# CH32V205 register map
Vendor: WCH Ltd.; File version: 1.0
Registers are 32-bit, read-write, reset 0x0 unless marked. A register's access mark holds for its fields unless they carry their own. Offsets are from the block's base; [hi:lo] are bit positions; {n}, {i} and the like mark numbered series.

## PWR — Power control
Base 0x40007000
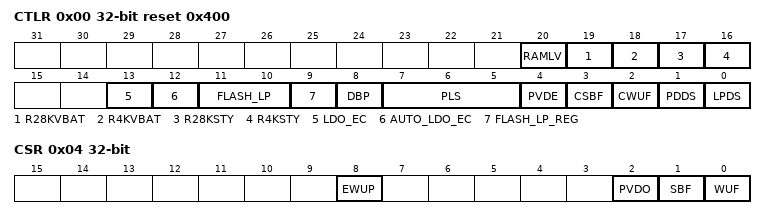
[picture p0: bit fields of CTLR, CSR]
0x00 CTLR reset 0x400 — Power control register (PWR_CTRL)
  [20] RAMLV — Ram LV Enable
  [19] R28KVBAT — VBAT 28k ram enable
  [18] R4KVBAT — VBAT 4k ram enable
  [17] R28KSTY — standby 28k ram enable
  [16] R4KSTY — standby 4k ram enable
  [13] LDO_EC — LDO energy conservation mode enable
  [12] AUTO_LDO_EC — Auto energy conservation mode of LDO after entering stop mode
  [11:10] FLASH_LP — configuration FLASH status
  [9] FLASH_LP_REG — FLASH Low-power enable
  [8] DBP — Disable Backup Domain write protection
  [7:5] PLS — PVD Level Selection
  [4] PVDE — Power Voltage Detector Enable
  [3] CSBF — Clear STANDBY Flag
  [2] CWUF — Clear Wake-up Flag
  [1] PDDS — Power Down Deep Sleep
  [0] LPDS — Low Power Deep Sleep
0x04 CSR access per field — Power control register(PWR_CSR)
  [8] EWUP rw — Enable WKUP pin
  [2] PVDO ro — PVD Output
  [1] SBF ro — STANDBY Flag
  [0] WUF ro — Wake-Up Flag

## EXTEN — Exten configuration
Base 0x40023800
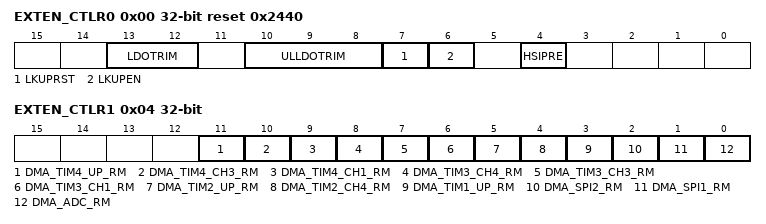
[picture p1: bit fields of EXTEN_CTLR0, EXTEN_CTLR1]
0x00 EXTEN_CTLR0 reset 0x2440 — EXTEN control register 0
  [13:12] LDOTRIM
  [10:8] ULLDOTRIM
  [7] LKUPRST — LOCKUP RESET
  [6] LKUPEN — LOCKUP_Eable
  [4] HSIPRE — Whether HSI is divided
0x04 EXTEN_CTLR1 — EXTEN control register 1
  [11] DMA_TIM4_UP_RM — Mapping of TIM4_UP on the DMA channel
  [10] DMA_TIM4_CH3_RM — Mapping of IM4_CH3 on the DMA channel
  [9] DMA_TIM4_CH1_RM — Mapping of TIM4_CH1 on the DMA channel
  [8] DMA_TIM3_CH4_RM — Mapping of TIM3_CH4 on the DMA channel
  [7] DMA_TIM3_CH3_RM — Mapping of TIM3_CH3 on the DMA channel
  [6] DMA_TIM3_CH1_RM — Mapping of TIM3_CH1 on the DMA channel
  [5] DMA_TIM2_UP_RM — Mapping of TIM2_UP on the DMA channel
  [4] DMA_TIM2_CH4_RM — Mapping of TIM2_CH4 on the DMA channel
  [3] DMA_TIM1_UP_RM — Mapping of TIM1_UP on the DMA channel
  [2] DMA_SPI2_RM — Mapping of SPI2 on the DMA channel
  [1] DMA_SPI1_RM — Mapping of SPI1 on the DMA channel
  [0] DMA_ADC_RM — Mapping of ADC on the DMA channel

## GPIOA — General purpose I/O
Base 0x40010800
Same registers: GPIOB 0x40010C00, GPIOC 0x40011000, GPIOD 0x40011400, GPIOE 0x40011800
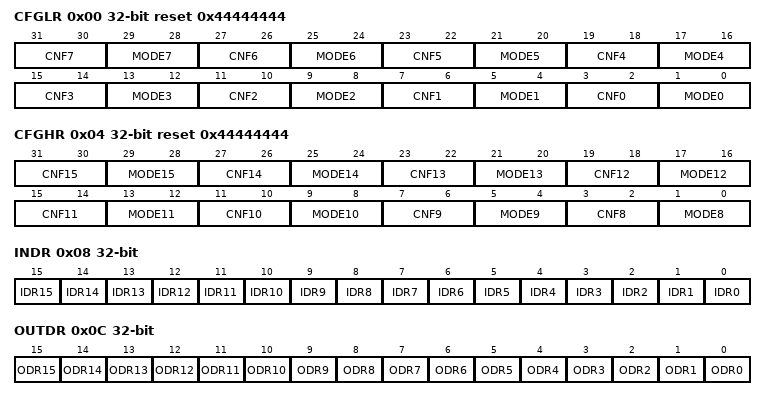
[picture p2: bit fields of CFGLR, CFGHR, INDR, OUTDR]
0x00 CFGLR reset 0x44444444 — Port configuration register low(GPIOn_CFGLR)
  [31:30] CNF7 — Port n.7 configuration bits
  [29:28] MODE7 — Port n.7 mode bits
  [27:26] CNF6 — Port n.6 configuration bits
  [25:24] MODE6 — Port n.6 mode bits
  [23:22] CNF5 — Port n.5 configuration bits
  [21:20] MODE5 — Port n.5 mode bits
  [19:18] CNF4 — Port n.4 configuration bits
  [17:16] MODE4 — Port n.4 mode bits
  [15:14] CNF3 — Port n.3 configuration bits
  [13:12] MODE3 — Port n.3 mode bits
  [11:10] CNF2 — Port n.2 configuration bits
  [9:8] MODE2 — Port n.2 mode bits
  [7:6] CNF1 — Port n.1 configuration bits
  [5:4] MODE1 — Port n.1 mode bits
  [3:2] CNF0 — Port n.0 configuration bits
  [1:0] MODE0 — Port n.0 mode bits
0x04 CFGHR reset 0x44444444 — Port configuration register high (GPIOn_CFGHR)
  [31:30] CNF15 — Port n.15 configuration bits
  [29:28] MODE15 — Port n.15 mode bits
  [27:26] CNF14 — Port n.14 configuration bits
  [25:24] MODE14 — Port n.14 mode bits
  [23:22] CNF13 — Port n.13 configuration bits
  [21:20] MODE13 — Port n.13 mode bits
  [19:18] CNF12 — Port n.12 configuration bits
  [17:16] MODE12 — Port n.12 mode bits
  [15:14] CNF11 — Port n.11 configuration bits
  [13:12] MODE11 — Port n.11 mode bits
  [11:10] CNF10 — Port n.10 configuration bits
  [9:8] MODE10 — Port n.10 mode bits
  [7:6] CNF9 — Port n.9 configuration bits
  [5:4] MODE9 — Port n.9 mode bits
  [3:2] CNF8 — Port n.8 configuration bits
  [1:0] MODE8 — Port n.8 mode bits
0x08 INDR ro — Port input data register (GPIOn_INDR)
  [n] IDR{n} (n=0..15) — Port input data
0x0C OUTDR — Port output data register (GPIOn_OUTDR)
  [n] ODR{n} (n=0..15) — Port output data
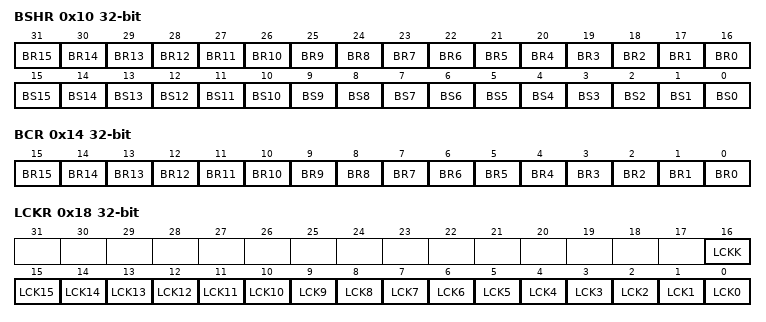
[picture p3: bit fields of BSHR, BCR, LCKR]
0x10 BSHR wo — Port bit set/reset register (GPIOn_BSHR)
  [n+16] BR{n} (n=0..15) — Reset bit {n}
  [n] BS{n} (n=3..15) — Set bit {n}
  [2] BS2 — Set bit 1
  [1] BS1 — Set bit 1
  [0] BS0 — Set bit 0
0x14 BCR wo — Port bit reset register (GPIOn_BCR)
  [n] BR{n} (n=3..15) — Reset bit {n}
  [2] BR2 — Reset bit 1
  [1] BR1 — Reset bit 1
  [0] BR0 — Reset bit 0
0x18 LCKR — Port configuration lock register
  [16] LCKK — Lock key
  [n] LCK{n} (n=0..15) — Port A Lock bit {n}
